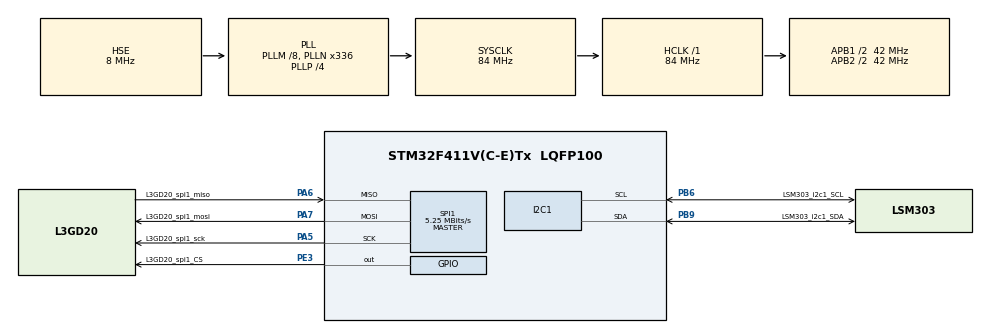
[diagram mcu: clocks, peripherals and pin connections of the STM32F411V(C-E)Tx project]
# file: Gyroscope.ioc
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Mcu.Family=STM32F4
Mcu.Name=STM32F411V(C-E)Tx
Mcu.Package=LQFP100
NVIC.PriorityGroup=NVIC_PRIORITYGROUP_4
NVIC.TIM2_IRQn=true\:0\:0\:false\:false\:true
PA5.GPIO_Label=L3GD20_spi1_sck
PA5.GPIO_Mode=GPIO_MODE_AF_PP
PA5.GPIO_PuPd=GPIO_NOPULL
PA5.GPIO_Speed=GPIO_SPEED_FREQ_VERY_HIGH
PA5.Mode=Full_Duplex_Master
PA5.Signal=SPI1_SCK
PA6.GPIO_Label=L3GD20_spi1_miso
PA6.GPIO_Mode=GPIO_MODE_AF_PP
PA6.GPIO_PuPd=GPIO_NOPULL
PA6.GPIO_Speed=GPIO_SPEED_FREQ_VERY_HIGH
PA6.Mode=Full_Duplex_Master
PA6.Signal=SPI1_MISO
PA7.GPIO_Label=L3GD20_spi1_mosi
PA7.GPIO_Mode=GPIO_MODE_AF_PP
PA7.GPIO_PuPd=GPIO_NOPULL
PA7.GPIO_Speed=GPIO_SPEED_FREQ_VERY_HIGH
PA7.Mode=Full_Duplex_Master
PA7.Signal=SPI1_MOSI
PB6.GPIO_Label=LSM303_i2c1_SCL
PB6.Mode=I2C
PB6.Signal=I2C1_SCL
PB9.GPIO_Label=LSM303_i2c1_SDA
PB9.Mode=I2C
PB9.Signal=I2C1_SDA
PE3.GPIO_Label=L3GD20_spi1_CS
PE3.GPIO_Speed=GPIO_SPEED_FREQ_HIGH
PE3.PinState=GPIO_PIN_RESET
PE3.Signal=GPIO_Output
PH0\ -\ OSC_IN.Mode=HSE-External-Oscillator
PH0\ -\ OSC_IN.Signal=RCC_OSC_IN
PH1\ -\ OSC_OUT.Mode=HSE-External-Oscillator
PH1\ -\ OSC_OUT.Signal=RCC_OSC_OUT
ProjectManager.HeapSize=0x200
ProjectManager.StackSize=0x400
ProjectManager.TargetToolchain=MDK-ARM V5
RCC.48MHZClocksFreq_Value=84000000
RCC.AHBFreq_Value=84000000
RCC.APB1CLKDivider=RCC_HCLK_DIV2
RCC.APB1Freq_Value=42000000
RCC.APB1TimFreq_Value=84000000
RCC.APB2CLKDivider=RCC_HCLK_DIV2
RCC.APB2Freq_Value=42000000
RCC.APB2TimFreq_Value=84000000
RCC.CortexFreq_Value=84000000
RCC.HCLKFreq_Value=84000000
RCC.HSE_VALUE=8000000
RCC.HSI_VALUE=16000000
RCC.LSE_VALUE=32768
RCC.PLLM=8
RCC.PLLN=336
RCC.PLLP=RCC_PLLP_DIV4
RCC.PLLSourceVirtual=RCC_PLLSOURCE_HSE
RCC.SYSCLKFreq_VALUE=84000000
RCC.SYSCLKSource=RCC_SYSCLKSOURCE_PLLCLK
RCC.VCOOutputFreq_Value=336000000
SPI1.BaudRatePrescaler=SPI_BAUDRATEPRESCALER_8
SPI1.CalculateBaudRate=5.25 MBits/s
SPI1.Mode=SPI_MODE_MASTER
TIM2.Period=200000
TIM2.Prescaler=84
VP_TIM2_VS_ClockSourceINT.Mode=Internal
board=Gyroscope

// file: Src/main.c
#include "main.h"
#include "stm32f4xx_hal.h"
#include "stm32f411e_discovery.h"
#include "stm32f411e_discovery_accelerometer.h"
#include "stm32f411e_discovery_gyroscope.h"
#include "lsm303dlhc_driver.h"
#include "lsm303dlhc.h"
#include "sensor.h"
#include "math.h"

I2C_HandleTypeDef hi2c1;
SPI_HandleTypeDef hspi1;
TIM_HandleTypeDef htim2;

double gyro_angle[3], acc_v[3], degree[3];

void SystemClock_Config(void);
void Error_Handler(void);
static void MX_GPIO_Init(void);
static void MX_SPI1_Init(void);
static void MX_TIM2_Init(void);
static void MX_I2C1_Init(void);
void SENSOR_Init(void);

int main(void)
{
  /* MCU Configuration----------------------------------------------------------*/

  /* Reset of all peripherals, Initializes the Flash interface and the Systick. */
  HAL_Init();

  /* Configure the system clock */
  SystemClock_Config();

  /* Initialize all configured peripherals */
  MX_GPIO_Init();
  MX_SPI1_Init();
  MX_TIM2_Init();
  MX_I2C1_Init();

  /* USER CODE BEGIN 2 */
	SENSOR_Init();
	HAL_TIM_Base_Start_IT(&htim2);

  while (1)
  {
  /* USER CODE END WHILE */

  /* USER CODE BEGIN 3 */

  }

}

/** System Clock Configuration
*/
void SystemClock_Config(void)
{

  RCC_OscInitTypeDef RCC_OscInitStruct;
  RCC_ClkInitTypeDef RCC_ClkInitStruct;

    /**Configure the main internal regulator output voltage
    */
  __HAL_RCC_PWR_CLK_ENABLE();

  __HAL_PWR_VOLTAGESCALING_CONFIG(PWR_REGULATOR_VOLTAGE_SCALE1);

    /**Initializes the CPU, AHB and APB busses clocks
    */
  RCC_OscInitStruct.OscillatorType = RCC_OSCILLATORTYPE_HSE;
  RCC_OscInitStruct.HSEState = RCC_HSE_ON;
  RCC_OscInitStruct.PLL.PLLState = RCC_PLL_ON;
  RCC_OscInitStruct.PLL.PLLSource = RCC_PLLSOURCE_HSE;
  RCC_OscInitStruct.PLL.PLLM = 8;
  RCC_OscInitStruct.PLL.PLLN = 336;
  RCC_OscInitStruct.PLL.PLLP = RCC_PLLP_DIV4;
  RCC_OscInitStruct.PLL.PLLQ = 4;
  if (HAL_RCC_OscConfig(&RCC_OscInitStruct) != HAL_OK)
  {
    Error_Handler();
  }

    /**Initializes the CPU, AHB and APB busses clocks
    */
  RCC_ClkInitStruct.ClockType = RCC_CLOCKTYPE_HCLK|RCC_CLOCKTYPE_SYSCLK
                              |RCC_CLOCKTYPE_PCLK1|RCC_CLOCKTYPE_PCLK2;
  RCC_ClkInitStruct.SYSCLKSource = RCC_SYSCLKSOURCE_PLLCLK;
  RCC_ClkInitStruct.AHBCLKDivider = RCC_SYSCLK_DIV1;
  RCC_ClkInitStruct.APB1CLKDivider = RCC_HCLK_DIV2;
  RCC_ClkInitStruct.APB2CLKDivider = RCC_HCLK_DIV2;

  if (HAL_RCC_ClockConfig(&RCC_ClkInitStruct, FLASH_LATENCY_2) != HAL_OK)
  {
    Error_Handler();
  }

    /**Configure the Systick interrupt time
    */
  HAL_SYSTICK_Config(HAL_RCC_GetHCLKFreq()/1000);

    /**Configure the Systick
    */
  HAL_SYSTICK_CLKSourceConfig(SYSTICK_CLKSOURCE_HCLK);

  /* SysTick_IRQn interrupt configuration */
  HAL_NVIC_SetPriority(SysTick_IRQn, 0, 0);
}

/* I2C1 init function */
static void MX_I2C1_Init(void)
{

  hi2c1.Instance = I2C1;
  hi2c1.Init.ClockSpeed = 100000;
  hi2c1.Init.DutyCycle = I2C_DUTYCYCLE_2;
  hi2c1.Init.OwnAddress1 = 0;
  hi2c1.Init.AddressingMode = I2C_ADDRESSINGMODE_7BIT;
  hi2c1.Init.DualAddressMode = I2C_DUALADDRESS_DISABLE;
  hi2c1.Init.OwnAddress2 = 0;
  hi2c1.Init.GeneralCallMode = I2C_GENERALCALL_DISABLE;
  hi2c1.Init.NoStretchMode = I2C_NOSTRETCH_DISABLE;
  if (HAL_I2C_Init(&hi2c1) != HAL_OK)
  {
    Error_Handler();
  }

}

/* SPI1 init function */
static void MX_SPI1_Init(void)
{

  hspi1.Instance = SPI1;
  hspi1.Init.Mode = SPI_MODE_MASTER;
  hspi1.Init.Direction = SPI_DIRECTION_2LINES;
  hspi1.Init.DataSize = SPI_DATASIZE_8BIT;
  hspi1.Init.CLKPolarity = SPI_POLARITY_LOW;
  hspi1.Init.CLKPhase = SPI_PHASE_1EDGE;
  hspi1.Init.NSS = SPI_NSS_SOFT;
  hspi1.Init.BaudRatePrescaler = SPI_BAUDRATEPRESCALER_8;
  hspi1.Init.FirstBit = SPI_FIRSTBIT_MSB;
  hspi1.Init.TIMode = SPI_TIMODE_DISABLE;
  hspi1.Init.CRCCalculation = SPI_CRCCALCULATION_DISABLE;
  hspi1.Init.CRCPolynomial = 10;
  if (HAL_SPI_Init(&hspi1) != HAL_OK)
  {
    Error_Handler();
  }

}

/* TIM2 init function */
static void MX_TIM2_Init(void)
{

  TIM_ClockConfigTypeDef sClockSourceConfig;
  TIM_MasterConfigTypeDef sMasterConfig;

  htim2.Instance = TIM2;
  htim2.Init.Prescaler = 84;
  htim2.Init.CounterMode = TIM_COUNTERMODE_UP;
  htim2.Init.Period = 200000;
  htim2.Init.ClockDivision = TIM_CLOCKDIVISION_DIV1;
  if (HAL_TIM_Base_Init(&htim2) != HAL_OK)
  {
    Error_Handler();
  }

  sClockSourceConfig.ClockSource = TIM_CLOCKSOURCE_INTERNAL;
  if (HAL_TIM_ConfigClockSource(&htim2, &sClockSourceConfig) != HAL_OK)
  {
    Error_Handler();
  }

  sMasterConfig.MasterOutputTrigger = TIM_TRGO_RESET;
  sMasterConfig.MasterSlaveMode = TIM_MASTERSLAVEMODE_DISABLE;
  if (HAL_TIMEx_MasterConfigSynchronization(&htim2, &sMasterConfig) != HAL_OK)
  {
    Error_Handler();
  }

}

/** Configure pins as
        * Analog
        * Input
        * Output
        * EVENT_OUT
        * EXTI
*/
static void MX_GPIO_Init(void)
{

  GPIO_InitTypeDef GPIO_InitStruct;

  /* GPIO Ports Clock Enable */
  __HAL_RCC_GPIOE_CLK_ENABLE();
  __HAL_RCC_GPIOH_CLK_ENABLE();
  __HAL_RCC_GPIOA_CLK_ENABLE();
  __HAL_RCC_GPIOB_CLK_ENABLE();

  /*Configure GPIO pin Output Level */
  HAL_GPIO_WritePin(L3GD20_spi1_CS_GPIO_Port, L3GD20_spi1_CS_Pin, GPIO_PIN_RESET);

  /*Configure GPIO pin : L3GD20_spi1_CS_Pin */
  GPIO_InitStruct.Pin = L3GD20_spi1_CS_Pin;
  GPIO_InitStruct.Mode = GPIO_MODE_OUTPUT_PP;
  GPIO_InitStruct.Pull = GPIO_NOPULL;
  GPIO_InitStruct.Speed = GPIO_SPEED_FREQ_HIGH;
  HAL_GPIO_Init(L3GD20_spi1_CS_GPIO_Port, &GPIO_InitStruct);

}

/* USER CODE BEGIN 4 */
// interupt timer
void HAL_TIM_PeriodElapsedCallback(TIM_HandleTypeDef *htim)
{
/*Timer 2, frequency 2Hz*/
	if(htim->Instance==htim2.Instance)
	{
	  XYZ_GYRO_Read(gyro_angle);
		XYZ_ACC_Read(acc_v);
		XYZ_ANGLE_Read(acc_v,degree);
	}
}

//function_kid
void SENSOR_Init()
{
	//Gyroscope
  HAL_GPIO_WritePin(GPIOE,GPIO_PIN_3,GPIO_PIN_RESET);
	BSP_GYRO_Init();
	HAL_Delay(500);
	GYRO_Calib();
	// Accelerometer
	BSP_ACCELERO_Init(); //fll scale 2G , +-2g
	HAL_Delay(500);
}

/* USER CODE END 4 */

void Error_Handler(void)
{
  while(1)
  {
  }
}

/************************ (C) COPYRIGHT STMicroelectronics *****END OF FILE****/
